# STM32L063 register map
File version: 1.0
CPU: CM0+ r0p0, little endian, MPU, no FPU, 4 interrupt priority bits
Registers are 32-bit, read-write, reset 0x0 unless marked. A register's access mark holds for its fields unless they carry their own. Offsets are from the block's base; [hi:lo] are bit positions; {n}, {i} and the like mark numbered series.

## NVIC — Nested Vectored Interrupt Controller
Base 0xE000E100
0x00 ISER — Interrupt Set Enable Register
  [31:0] SETENA
0x80 ICER — Interrupt Clear Enable Register
  [31:0] CLRENA
0x100 ISPR — Interrupt Set-Pending Register
  [31:0] SETPEND
0x180 ICPR — Interrupt Clear-Pending Register
  [31:0] CLRPEND
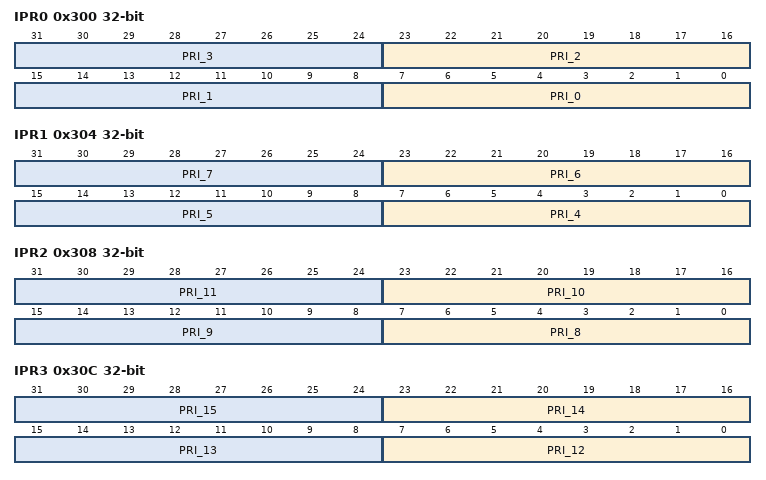
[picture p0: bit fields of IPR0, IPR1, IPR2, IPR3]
0x300 IPR0 — Interrupt Priority Register 0
  [8n+7:8n] PRI_{n} (n=0..3) — priority for interrupt {n}
0x304 IPR1 — Interrupt Priority Register 1
  [8n-25:8n-32] PRI_{n} (n=4..7) — priority for interrupt n
0x308 IPR2 — Interrupt Priority Register 2
  [8n-57:8n-64] PRI_{n} (n=8..11) — priority for interrupt n
0x30C IPR3 — Interrupt Priority Register 3
  [8n-89:8n-96] PRI_{n} (n=12..15) — priority for interrupt n
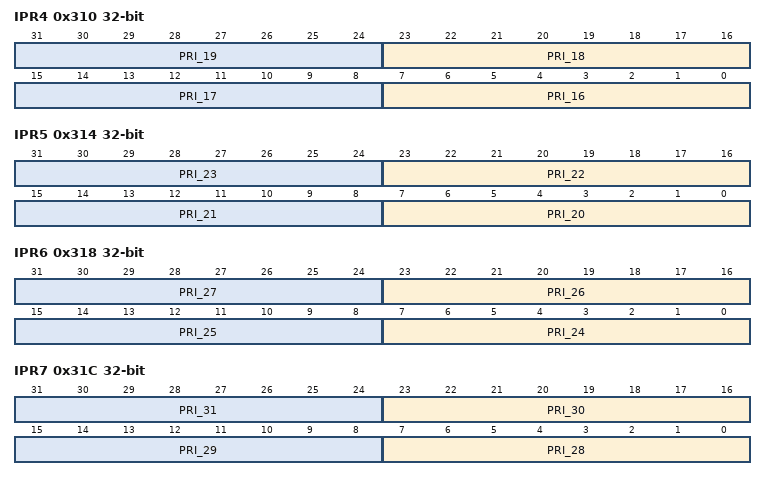
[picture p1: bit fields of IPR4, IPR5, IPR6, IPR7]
0x310 IPR4 — Interrupt Priority Register 4
  [8n-121:8n-128] PRI_{n} (n=16..19) — priority for interrupt n
0x314 IPR5 — Interrupt Priority Register 5
  [8n-153:8n-160] PRI_{n} (n=20..23) — priority for interrupt n
0x318 IPR6 — Interrupt Priority Register 6
  [8n-185:8n-192] PRI_{n} (n=24..27) — priority for interrupt n
0x31C IPR7 — Interrupt Priority Register 7
  [8n-217:8n-224] PRI_{n} (n=28..31) — priority for interrupt n

## USB_SRAM — Universal serial bus full-speed device interface
Base 0x40006000
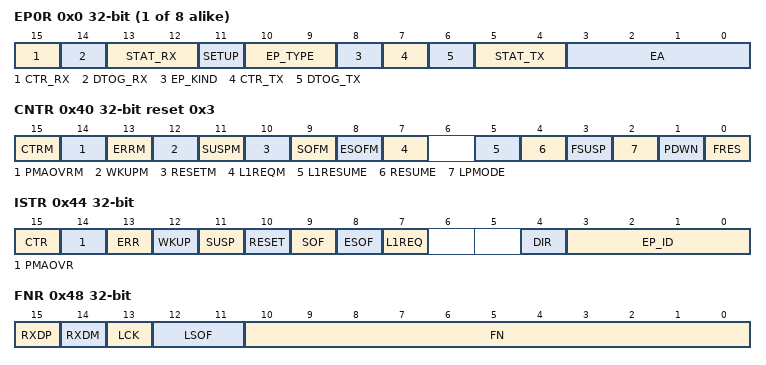
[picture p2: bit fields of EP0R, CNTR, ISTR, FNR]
{0x0+4i} EP{i}R (i=0..7) — endpoint {i} register
  [15] CTR_RX — Correct transfer for reception
  [14] DTOG_RX — Data Toggle, for reception transfers
  [13:12] STAT_RX — Status bits, for reception transfers
  [11] SETUP — Setup transaction completed
  [10:9] EP_TYPE — Endpoint type
  [8] EP_KIND — Endpoint kind
  [7] CTR_TX — Correct Transfer for transmission
  [6] DTOG_TX — Data Toggle, for transmission transfers
  [5:4] STAT_TX — Status bits, for transmission transfers
  [3:0] EA — Endpoint address
0x40 CNTR reset 0x3 — control register
  [15] CTRM — Correct transfer interrupt mask
  [14] PMAOVRM — Packet memory area over / underrun interrupt mask
  [13] ERRM — Error interrupt mask
  [12] WKUPM — Wakeup interrupt mask
  [11] SUSPM — Suspend mode interrupt mask
  [10] RESETM — USB reset interrupt mask
  [9] SOFM — Start of frame interrupt mask
  [8] ESOFM — Expected start of frame interrupt mask
  [7] L1REQM — LPM L1 state request interrupt mask
  [5] L1RESUME — LPM L1 Resume request
  [4] RESUME — Resume request
  [3] FSUSP — Force suspend
  [2] LPMODE — Low-power mode
  [1] PDWN — Power down
  [0] FRES — Force USB Reset
0x44 ISTR access per field — interrupt status register
  [15] CTR ro — Correct transfer
  [14] PMAOVR rw — Packet memory area over / underrun
  [13] ERR rw — Error
  [12] WKUP rw — Wakeup
  [11] SUSP rw — Suspend mode request
  [10] RESET rw — reset request
  [9] SOF rw — start of frame
  [8] ESOF rw — Expected start frame
  [7] L1REQ rw — LPM L1 state request
  [4] DIR ro — Direction of transaction
  [3:0] EP_ID ro — Endpoint Identifier
0x48 FNR ro — frame number register
  [15] RXDP — Receive data + line status
  [14] RXDM — Receive data - line status
  [13] LCK — Locked
  [12:11] LSOF — Lost SOF
  [10:0] FN — Frame number
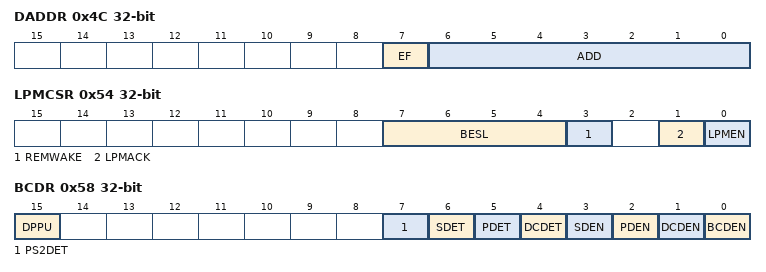
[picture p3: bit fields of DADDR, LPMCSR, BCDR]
0x4C DADDR — device address
  [7] EF — Enable function
  [6:0] ADD — Device address
0x50 BTABLE — Buffer table address
  [15:3] BTABLE — Buffer table
0x54 LPMCSR access per field — LPM control and status register
  [7:4] BESL ro — BESL value
  [3] REMWAKE ro — bRemoteWake value
  [1] LPMACK rw — LPM Token acknowledge enable
  [0] LPMEN rw — LPM support enable
0x58 BCDR access per field — Battery charging detector
  [15] DPPU rw — DP pull-up control
  [7] PS2DET ro — DM pull-up detection status
  [6] SDET ro — Secondary detection
  [5] PDET ro — Primary detection
  [4] DCDET ro — Data contact detection
  [3] SDEN rw — Secondary detection
  [2] PDEN rw — Primary detection
  [1] DCDEN rw — Data contact detection
  [0] BCDEN rw — Battery charging detector
